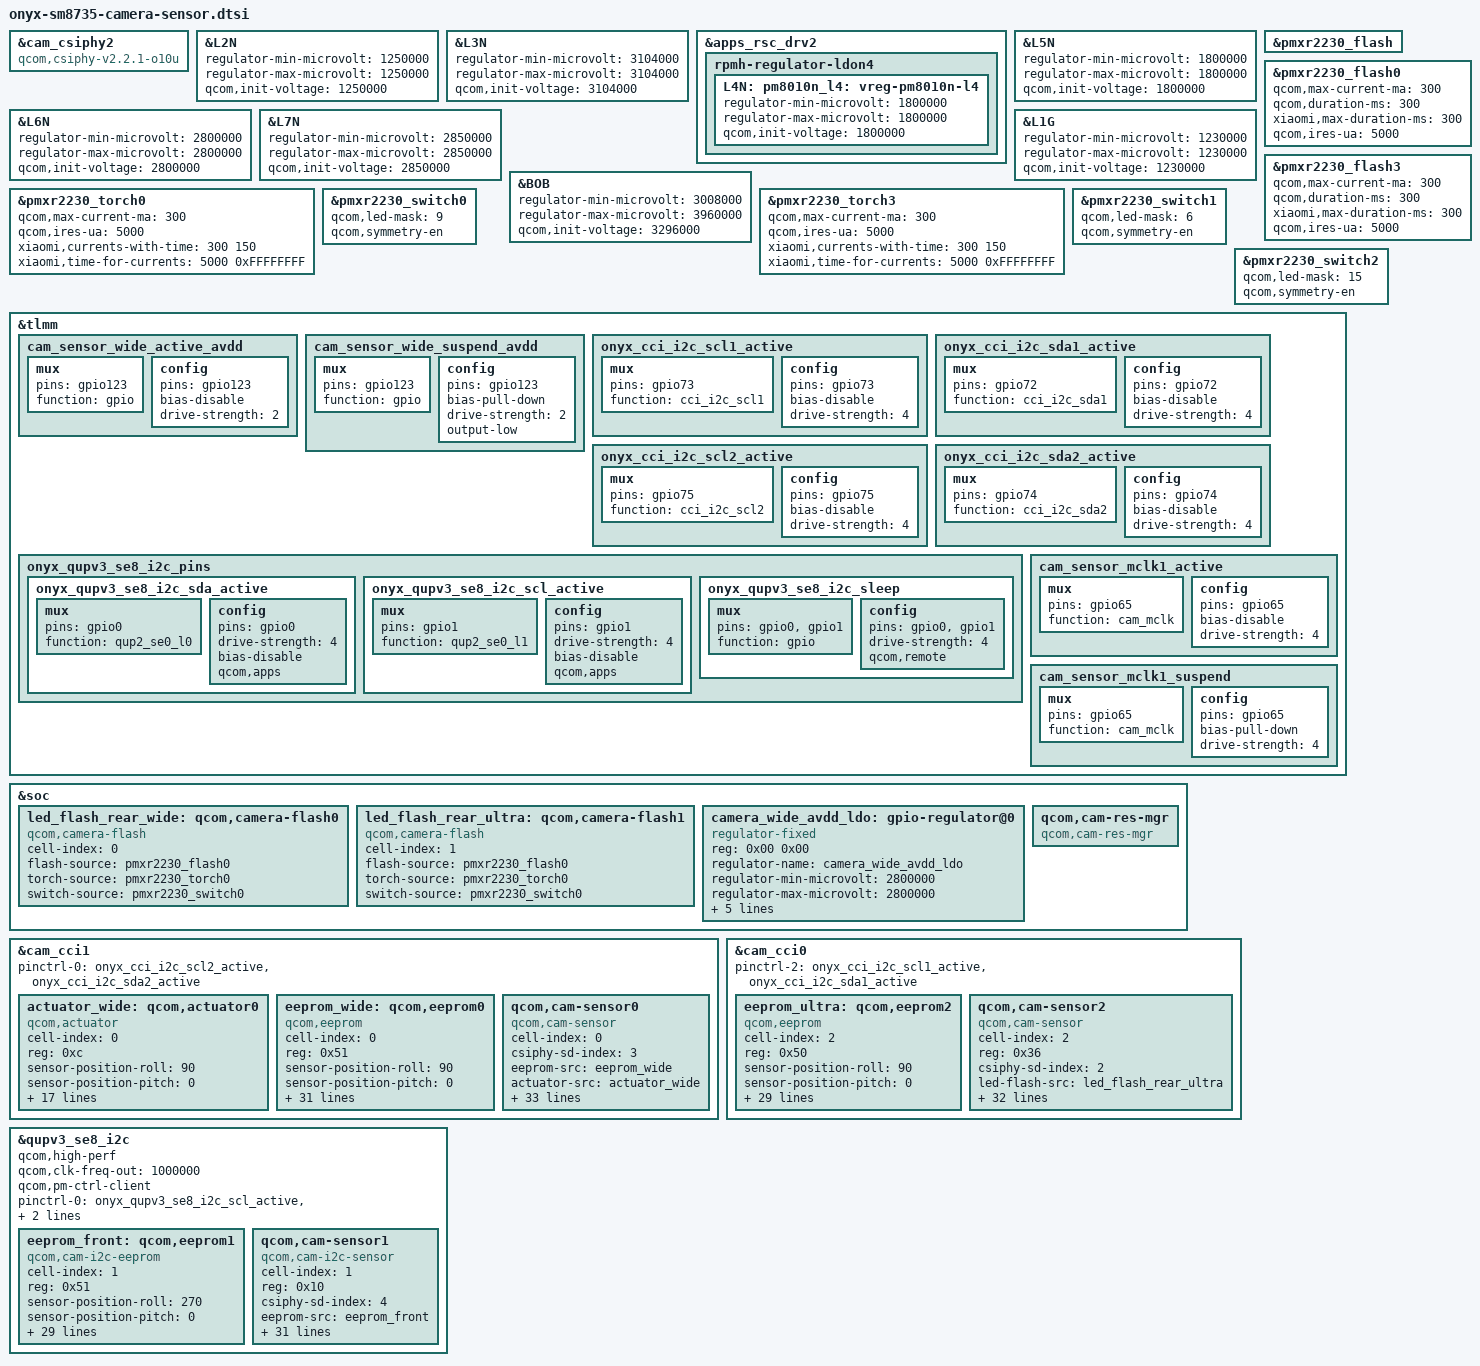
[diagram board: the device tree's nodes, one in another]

#include <dt-bindings/msm-camera.h>

// uw sensor
&cam_csiphy2 {
	compatible = "qcom,csiphy-v2.2.1-o10u", "qcom,csiphy";
};

&L2N {
	regulator-min-microvolt = <1250000>;
	regulator-max-microvolt = <1250000>;
	qcom,init-voltage = <1250000>;
};

&L3N {
	regulator-min-microvolt = <3104000>;
	regulator-max-microvolt = <3104000>;
	qcom,init-voltage = <3104000>;
};

&apps_rsc_drv2 {
	rpmh-regulator-ldon4 {
		status = "ok";
		L4N: pm8010n_l4: vreg-pm8010n-l4 {
			regulator-min-microvolt = <1800000>;
			regulator-max-microvolt = <1800000>;
			qcom,init-voltage = <1800000>;
			status = "ok";
		};
	};
};

&L5N {
	regulator-min-microvolt = <1800000>;
	regulator-max-microvolt = <1800000>;
	qcom,init-voltage = <1800000>;
};

&L6N {
	regulator-min-microvolt = <2800000>;
	regulator-max-microvolt = <2800000>;
	qcom,init-voltage = <2800000>;
};

&L7N {
	regulator-min-microvolt = <2850000>;
	regulator-max-microvolt = <2850000>;
	qcom,init-voltage = <2850000>;
};

&L1G {
	regulator-min-microvolt = <1230000>;
	regulator-max-microvolt = <1230000>;
	qcom,init-voltage = <1230000>;
};

&BOB {
	regulator-min-microvolt = <3008000>;
	regulator-max-microvolt = <3960000>;
	qcom,init-voltage = <3296000>;
};

&pmxr2230_flash {
	status = "ok";
};

&pmxr2230_flash0 {
	qcom,max-current-ma = <300>;
	qcom,duration-ms = <300>;
	xiaomi,max-duration-ms = <300>;
	qcom,ires-ua = <5000>;
};

&pmxr2230_flash3 {
	qcom,max-current-ma = <300>;
	qcom,duration-ms = <300>;
	xiaomi,max-duration-ms = <300>;
	qcom,ires-ua = <5000>;
};

&pmxr2230_torch0 {
	qcom,max-current-ma = <300>;
	qcom,ires-ua = <5000>;
	xiaomi,currents-with-time = <300 150>;
	xiaomi,time-for-currents = <5000 0xFFFFFFFF>;
};

&pmxr2230_torch3 {
	qcom,max-current-ma = <300>;
	qcom,ires-ua = <5000>;
	xiaomi,currents-with-time = <300 150>;
	xiaomi,time-for-currents = <5000 0xFFFFFFFF>;
};

&pmxr2230_switch0 {
	qcom,led-mask = <9>;  /*channels 1 & 4*/
	qcom,symmetry-en;
};

&pmxr2230_switch1 {
	qcom,led-mask = <6>;  /*channels 2 & 3*/
	qcom,symmetry-en;
};

&pmxr2230_switch2{
	qcom,led-mask = <15>; /*all channels*/
	qcom,symmetry-en;
};

&tlmm {
	//wide avdd
	cam_sensor_wide_active_avdd: cam_sensor_wide_active_avdd {
		mux {
			pins = "gpio123";
			function = "gpio";
		};
		config {
			pins = "gpio123";
			bias-disable; /* No PULL */
			drive-strength = <2>; /* 2 MA */
		};
	};

	cam_sensor_wide_suspend_avdd: cam_sensor_wide_suspend_avdd {
		mux {
			pins = "gpio123";
			function = "gpio";
		};
		config {
			pins = "gpio123";
			bias-pull-down; /* PULL DOWN */
			drive-strength = <2>; /* 2 MA */
			output-low;
		};
	};
	//ultra cci
	onyx_cci_i2c_scl1_active: onyx_cci_i2c_scl1_active {
		mux {
			/* CLK, DATA */
			pins = "gpio73";
			function = "cci_i2c_scl1";
		};
		config {
			pins = "gpio73";
			bias-disable; /* NO PULL */
			drive-strength = <4>; /* 2 MA */
		};
	};
	onyx_cci_i2c_sda1_active: onyx_cci_i2c_sda1_active {
		mux {
			/* CLK, DATA */
			pins = "gpio72";
			function = "cci_i2c_sda1";
		};
		config {
			pins = "gpio72";
			bias-disable; /* NO PULL */
			drive-strength = <4>; /* 2 MA */
		};
	};
	//wide cci
	onyx_cci_i2c_scl2_active: onyx_cci_i2c_scl2_active {
		mux {
			/* CLK, DATA */
			pins = "gpio75";
			function = "cci_i2c_scl2";
		};
		config {
			pins = "gpio75";
			bias-disable; /* NO PULL */
			drive-strength = <4>; /* 2 MA */
		};
	};
	onyx_cci_i2c_sda2_active: onyx_cci_i2c_sda2_active {
		mux {
			/* CLK, DATA */
			pins = "gpio74";
			function = "cci_i2c_sda2";
		};
		config {
			pins = "gpio74";
			bias-disable; /* NO PULL */
			drive-strength = <4>; /* 2 MA */
		};
	};
	onyx_qupv3_se8_i2c_pins: onyx_qupv3_se8_i2c_pins {
		onyx_qupv3_se8_i2c_sda_active: onyx_qupv3_se8_i2c_sda_active {
			mux {
				pins = "gpio0";
				function = "qup2_se0_l0";
			};

			config {
				pins = "gpio0";
				drive-strength = <4>;
				bias-disable;
				qcom,apps;
			};
		};

		onyx_qupv3_se8_i2c_scl_active: onyx_qupv3_se8_i2c_scl_active {
			mux {
				pins = "gpio1";
				function = "qup2_se0_l1";
			};

			config {
				pins = "gpio1";
				drive-strength = <4>;
				bias-disable;
				qcom,apps;
			};
		};
		onyx_qupv3_se8_i2c_sleep: onyx_qupv3_se8_i2c_sleep {
			mux {
				pins = "gpio0", "gpio1";
				function = "gpio";
			};

			config {
				pins = "gpio0", "gpio1";
				drive-strength = <4>;
				qcom,remote;
			};
		};
	};

	cam_sensor_mclk1_active: cam_sensor_mclk1_active {
	/* MCLK1 */
		mux {
			pins = "gpio65";
			function = "cam_mclk";
		};

		config {
			pins = "gpio65";
			bias-disable; /* No PULL */
			drive-strength = <4>; /* 2 MA */
		};
	};
	cam_sensor_mclk1_suspend: cam_sensor_mclk1_suspend {
	/* MCLK1 */
		mux {
			pins = "gpio65";
			function = "cam_mclk";
		};

		config {
			pins = "gpio65";
			bias-pull-down; /* PULL DOWN */
			drive-strength = <4>; /* 2 MA */
		};
	};
};

&soc {

	led_flash_rear_wide: qcom,camera-flash0 {
		cell-index = <0>;
		compatible = "qcom,camera-flash";
		flash-source = <&pmxr2230_flash0>;
		torch-source = <&pmxr2230_torch0>;
		switch-source = <&pmxr2230_switch0>;
		status = "ok";
	};

	led_flash_rear_ultra: qcom,camera-flash1 {
		cell-index = <1>;
		compatible = "qcom,camera-flash";
		flash-source = <&pmxr2230_flash0>;
		torch-source = <&pmxr2230_torch0>;
		switch-source = <&pmxr2230_switch0>;
		status = "ok";
	};

	//wide avdd
	camera_wide_avdd_ldo: gpio-regulator@0 {
		compatible = "regulator-fixed";
		reg = <0x00 0x00>;
		regulator-name = "camera_wide_avdd_ldo";
		regulator-min-microvolt = <2800000>;
		regulator-max-microvolt = <2800000>;
		regulator-enable-ramp-delay = <100>;
		enable-active-high;
		gpio = <&tlmm 123 0>;
		pinctrl-names = "wide_avdd_active", "wide_avdd_suspend";
		pinctrl-0 = <&cam_sensor_wide_active_avdd
					 &cam_sensor_wide_suspend_avdd>;
	};

	qcom,cam-res-mgr {
		compatible = "qcom,cam-res-mgr";
		status = "ok";
	};
};

&cam_cci1 {
	pinctrl-0 = <&onyx_cci_i2c_scl2_active &onyx_cci_i2c_sda2_active>;
	// wide actuator
	actuator_wide: qcom,actuator0 {
		cell-index = <0>;
		reg = <0xc>;
		compatible = "qcom,actuator";
		sensor-position-roll = <90>;
		sensor-position-pitch = <0>;
		sensor-position-yaw = <180>;
		cam_vio-supply = <&L4N>;
		cam_vdig-supply = <&L1N>;
		cam_clk-supply = <&cam_cc_titan_top_gdsc>;
		cam_vaf-supply = <&L3N>;
		cam_vana-supply = <&camera_wide_avdd_ldo>;
		cam_bob-supply = <&BOB>;
		regulator-names = "cam_vio", "cam_vdig", "cam_clk", "cam_vana", "cam_vaf", "cam_bob";
		rgltr-cntrl-support;
		rgltr-min-voltage = <1800000 1104000 0 2800000 3104000 3008000>;
		rgltr-max-voltage = <1800000 1104000 0 2800000 3104000 3960000>;
		rgltr-load-current = <6000 660000 0 82000 150000 2000000>;
		cci-master = <CCI_MASTER_0>;
		status = "ok";
	};

	eeprom_wide: qcom,eeprom0 {
		cell-index = <0>;
		reg = <0x51>;
		compatible = "qcom,eeprom";
		sensor-position-roll = <90>;
		sensor-position-pitch = <0>;
		sensor-position-yaw = <180>;
		cam_vio-supply = <&L4N>;
		cam_vdig-supply = <&L1N>;
		cam_clk-supply = <&cam_cc_titan_top_gdsc>;
		cam_vaf-supply = <&L3N>;
		cam_vana-supply = <&camera_wide_avdd_ldo>;
		cam_bob-supply = <&BOB>;
		regulator-names = "cam_vio", "cam_vdig", "cam_clk", "cam_vana", "cam_bob";
		rgltr-cntrl-support;
		rgltr-min-voltage = <1800000 1104000 0 2800000 3008000>;
		rgltr-max-voltage = <1800000 1104000 0 2800000 3960000>;
		rgltr-load-current = <6000 660000 0 82000 2000000>;
		gpio-no-mux = <0>;
		pinctrl-names = "cam_default", "cam_suspend";
		pinctrl-0 = <&cam_sensor_mclk3_active
				&cam_sensor_active_rst2>;
		pinctrl-1 = <&cam_sensor_mclk3_suspend
				&cam_sensor_suspend_rst2>;
		gpios = <&tlmm 67 0>,
			<&tlmm 180 0>;
		gpio-reset = <1>;
		gpio-req-tbl-num = <0 1>;
		gpio-req-tbl-flags = <1 0>;
		gpio-req-tbl-label = "CAMIF_MCLK3",
					"CAM_RESET2";
		cci-master = <CCI_MASTER_0>;
		clocks = <&cambistmclkcc CAM_BIST_MCLK_CC_MCLK3_CLK>;
		clock-names = "cam_clk";
		clock-cntl-level = "nominal";
		clock-rates = <19200000>;
		status = "ok";
	};

	qcom,cam-sensor0 {
		cell-index = <0>;
		compatible = "qcom,cam-sensor";
		csiphy-sd-index = <3>;
		eeprom-src = <&eeprom_wide>;
		actuator-src = <&actuator_wide>;
		led-flash-src = <&led_flash_rear_wide>;
		sensor-position-roll = <90>;
		sensor-position-pitch = <0>;
		sensor-position-yaw = <180>;
		cam_vio-supply = <&L4N>;
		cam_vdig-supply = <&L1N>;
		cam_clk-supply = <&cam_cc_titan_top_gdsc>;
		cam_vana-supply = <&camera_wide_avdd_ldo>;
		cam_bob-supply = <&BOB>;
		regulator-names = "cam_vio", "cam_vdig", "cam_clk", "cam_vana", "cam_bob";
		rgltr-cntrl-support;
		rgltr-min-voltage = <1800000 1104000 0 2800000 3008000>;
		rgltr-max-voltage = <1800000 1104000 0 2800000 3960000>;
		rgltr-load-current = <6000 660000 0 82000 2000000>;
		gpio-no-mux = <0>;
		pinctrl-names = "cam_default", "cam_suspend";
		pinctrl-0 = <&cam_sensor_mclk3_active
		 		&cam_sensor_active_rst2>;
		pinctrl-1 = <&cam_sensor_mclk3_suspend
		 		&cam_sensor_suspend_rst2>;
		gpios = <&tlmm 67 0>,
			<&tlmm 180 0>;
		gpio-reset = <1>;
		gpio-req-tbl-num = <0 1>;
		gpio-req-tbl-flags = <1 0>;
		gpio-req-tbl-label = "CAMIF_MCLK3",
					"CAM_RESET2";
		cci-master = <CCI_MASTER_0>;
		clocks = <&cambistmclkcc CAM_BIST_MCLK_CC_MCLK3_CLK>;
		clock-names = "cam_clk";
		clock-cntl-level = "nominal";
		clock-rates = <19200000>;
		status = "ok";
	};
};
&cam_cci0 {
	pinctrl-2 = <&onyx_cci_i2c_scl1_active &onyx_cci_i2c_sda1_active>;

	eeprom_ultra: qcom,eeprom2 {
		cell-index = <2>;
		reg = <0x50>;
		compatible = "qcom,eeprom";
		sensor-position-roll = <90>;
		sensor-position-pitch = <0>;
		sensor-position-yaw = <180>;
		cam_vio-supply = <&L4N>;
		cam_vdig-supply = <&L1G>;
		cam_clk-supply = <&cam_cc_titan_top_gdsc>;
		cam_vana-supply = <&L7N>;
		cam_bob-supply = <&BOB>;
		regulator-names = "cam_vio", "cam_vdig","cam_clk", "cam_vana", "cam_bob";
		rgltr-cntrl-support;
		rgltr-min-voltage = <1800000 1230000 0 2850000 3008000>;
		rgltr-max-voltage = <1800000 1230000 0 2850000 3960000>;
		rgltr-load-current = <200 150000 0  30000 2000000>;
		gpio-no-mux = <0>;
		pinctrl-names = "cam_default", "cam_suspend";
		pinctrl-0 = <&cam_sensor_mclk1_active
					&cam_sensor_active_rst1>;
		pinctrl-1 = <&cam_sensor_mclk1_suspend
					&cam_sensor_suspend_rst1>;
		gpios = <&tlmm 65 0>, <&tlmm 28 0>;
		gpio-reset = <1>;
		gpio-req-tbl-num = <0 1>;
		gpio-req-tbl-flags = <1 0>;
		gpio-req-tbl-label = "CAMUW_MCLK1", "CAMUW_RESET1";
		clocks = <&cambistmclkcc CAM_BIST_MCLK_CC_MCLK1_CLK>;
		cci-master = <CCI_MASTER_1>;
		clock-names = "cam_clk";
		clock-cntl-level = "nominal";
		clock-rates = <19200000>;
		status = "ok";
	};

	// uw sensor
	qcom,cam-sensor2 {
		cell-index = <2>;
		reg = <0x36>;
		compatible = "qcom,cam-sensor";
		csiphy-sd-index = <2>;
		led-flash-src = <&led_flash_rear_ultra>;
		eeprom-src = <&eeprom_ultra>;
		sensor-position-roll = <90>;
		sensor-position-pitch = <0>;
		sensor-position-yaw = <180>;
		cam_vio-supply = <&L4N>;
		cam_vdig-supply = <&L1G>;
		cam_clk-supply = <&cam_cc_titan_top_gdsc>;
		cam_vana-supply = <&L7N>;
		cam_bob-supply = <&BOB>;
		regulator-names = "cam_vio", "cam_vdig","cam_clk", "cam_vana", "cam_bob";
		rgltr-cntrl-support;
		rgltr-min-voltage = <1800000 1230000 0 2850000 3008000>;
		rgltr-max-voltage = <1800000 1230000 0 2850000 3960000>;
		rgltr-load-current = <200 150000 0 30000 2000000>;
		gpio-no-mux = <0>;
		pinctrl-names = "cam_default", "cam_suspend";
		pinctrl-0 = <&cam_sensor_mclk1_active
					&cam_sensor_active_rst1>;
		pinctrl-1 = <&cam_sensor_mclk1_suspend
					&cam_sensor_suspend_rst1>;
		gpios = <&tlmm 65 0>, <&tlmm 28 0>;
		gpio-reset = <1>;
		gpio-req-tbl-num = <0 1>;
		gpio-req-tbl-flags = <1 0>;
		gpio-req-tbl-label = "CAMUW_MCLK1", "CAMUW_RESET1";
		clocks = <&cambistmclkcc CAM_BIST_MCLK_CC_MCLK1_CLK>;
		cci-master = <CCI_MASTER_1>;
		clock-names = "cam_clk";
		clock-cntl-level = "nominal";
		clock-rates = <19200000>;
		status = "ok";
	};
};

&qupv3_se8_i2c {
	status = "ok";
	qcom,high-perf;
	qcom,clk-freq-out = <1000000>;
	qcom,pm-ctrl-client;
	pinctrl-0 = <&onyx_qupv3_se8_i2c_scl_active>, <&onyx_qupv3_se8_i2c_sda_active>;
	pinctrl-1 = <&onyx_qupv3_se8_i2c_sleep>;

	eeprom_front: qcom,eeprom1 {
		cell-index = <1>;
		reg = <0x51>;
		compatible = "qcom,cam-i2c-eeprom";
		sensor-position-roll = <270>;
		sensor-position-pitch = <0>;
		sensor-position-yaw = <0>;
		cam_vana-supply = <&L6N>;
		cam_vio-supply = <&L5N>;
		cam_vdig-supply = <&L2N>;
		cam_clk-supply = <&cam_cc_titan_top_gdsc>;
		cam_bob-supply = <&BOB>;
		regulator-names = "cam_vana", "cam_vio",
			"cam_vdig", "cam_clk", "cam_bob";
		rgltr-cntrl-support;
		aon-camera-id = <AON_CAM1>;
		rgltr-min-voltage = <2800000 1800000 1250000 0 3008000>;
		rgltr-max-voltage = <2800000 1800000 1250000 0 3960000>;
		rgltr-load-current = <60000 500 160000 0 2000000>;
		gpio-no-mux = <0>;
		pinctrl-names = "cam_default", "cam_suspend";
		pinctrl-0 = <&cam_sensor_mclk4_active
			&cam_sensor_active_rst3>;
		pinctrl-1 = <&cam_sensor_mclk4_suspend
			&cam_sensor_suspend_rst3>;
		gpios = <&tlmm 68 0>, <&tlmm 3 0>;
		gpio-reset = <1>;
		gpio-req-tbl-num = <0 1>;
		gpio-req-tbl-flags = <1 0>;
		gpio-req-tbl-label = "CAMIF_MCLK4", "CAM_RESET3";
		clocks = <&cambistmclkcc CAM_BIST_MCLK_CC_MCLK4_CLK>;
		clock-names = "cam_clk";
		clock-cntl-level = "nominal";
		clock-rates = <19200000>;
		status = "ok";
	};

	// Front Sensor
	qcom,cam-sensor1 {
		cell-index = <1>;
		reg = <0x10>;
		compatible = "qcom,cam-i2c-sensor";
		csiphy-sd-index = <4>;
		eeprom-src = <&eeprom_front>;
		sensor-position-roll = <270>;
		sensor-position-pitch = <0>;
		sensor-position-yaw = <0>;
		cam_vana-supply = <&L6N>;
		cam_vio-supply = <&L5N>;
		cam_vdig-supply = <&L2N>;
		cam_clk-supply = <&cam_cc_titan_top_gdsc>;
		cam_bob-supply = <&BOB>;
		regulator-names = "cam_vana", "cam_vio",
			"cam_vdig", "cam_clk", "cam_bob";
		rgltr-cntrl-support;
		aon-camera-id = <AON_CAM1>;
		rgltr-min-voltage = <2800000 1800000 1250000 0 3008000>;
		rgltr-max-voltage = <2800000 1800000 1250000 0 3960000>;
		rgltr-load-current = <60000 500 160000 0 2000000>;
		gpio-no-mux = <0>;
		pinctrl-names = "cam_default", "cam_suspend";
		pinctrl-0 = <&cam_sensor_mclk4_active
			&cam_sensor_active_rst3>;
		pinctrl-1 = <&cam_sensor_mclk4_suspend
			&cam_sensor_suspend_rst3>;
		gpios = <&tlmm 68 0>, <&tlmm 3 0>;
		gpio-reset = <1>;
		gpio-req-tbl-num = <0 1>;
		gpio-req-tbl-flags = <1 0>;
		gpio-req-tbl-label = "CAMIF_MCLK4", "CAM_RESET3";
		clocks = <&cambistmclkcc CAM_BIST_MCLK_CC_MCLK4_CLK>;
		clock-names = "cam_clk";
		clock-cntl-level = "nominal";
		clock-rates = <19200000>;
		status = "ok";
	};
};

